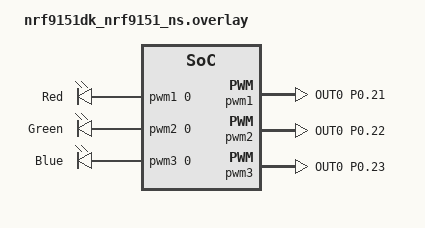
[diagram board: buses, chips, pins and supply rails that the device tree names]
// To get started, press Ctrl+Space to bring up the completion menu and view the available nodes.

// You can also use the buttons in the sidebar to perform actions on nodes.
// Actions currently available include:

// * Enabling / disabling the node
// * Adding the bus to a bus
// * Removing the node
// * Connecting ADC channels

// For more help, browse the DeviceTree documentation at https://docs.zephyrproject.org/latest/guides/dts/index.html
// You can also visit the nRF DeviceTree extension documentation at https://docs.nordicsemi.com/bundle/nrf-connect-vscode/page/guides/ncs_configure_app.html#devicetree-support-in-the-extension

/ {

    pwmleds_rgb{
        compatible = "pwm-leds";

        pwm_led_r: pwm_led_r {
            pwms = <&pwm1 0 PWM_MSEC(2) PWM_POLARITY_NORMAL>;
            label = "Red";
            status = "okay";
        };

        pwm_led_g: pwm_led_g {
            pwms = <&pwm2 0 PWM_MSEC(2) PWM_POLARITY_NORMAL>;
            label = "Green";
            status = "okay";
        };

        pwm_led_b: pwm_led_b {
            pwms = <&pwm3 0 PWM_MSEC(2) PWM_POLARITY_NORMAL>;
            label = "Blue";
            status = "okay";
        };
    };

};

&pwm1 {
    status = "okay";
    pinctrl-0 = <&pwm1_default>;
    pinctrl-1 = <&pwm1_sleep>;
    pinctrl-names = "default", "sleep";
};

&pwm2 {
    status = "okay";
    pinctrl-0 = <&pwm2_default>;
    pinctrl-1 = <&pwm2_sleep>;
    pinctrl-names = "default", "sleep";
};

&pwm3 {
    status = "okay";
    pinctrl-0 = <&pwm3_default>;
    pinctrl-1 = <&pwm3_sleep>;
    pinctrl-names = "default", "sleep";
};

// ----- PINCTROL FOR PWMS ----- //
&pinctrl {

    pwm1_default: pwm1_default {
        group1{
            psels = <NRF_PSEL(PWM_OUT0, 0, 21)>;
            nordic,invert;
        };
    };
    pwm1_sleep: pwm1_sleep {
        group1{
            psels = <NRF_PSEL(PWM_OUT0, 0, 21)>;
            low-power-enable;
        };
    };

    pwm2_default: pwm2_default {
        group1{
            psels = <NRF_PSEL(PWM_OUT0, 0, 22)>;
            nordic,invert;
        };
    };
    pwm2_sleep: pwm2_sleep {
        group1{
            psels = <NRF_PSEL(PWM_OUT0, 0, 22)>;
            low-power-enable;
        };
    };

    pwm3_default: pwm3_default {
        group1{
            psels = <NRF_PSEL(PWM_OUT0, 0, 23)>;
            nordic,invert;
        };
    };
    pwm3_sleep: pwm3_sleep {
        group1{
            psels = <NRF_PSEL(PWM_OUT0, 0, 23)>;
            low-power-enable;
        };
    };
};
